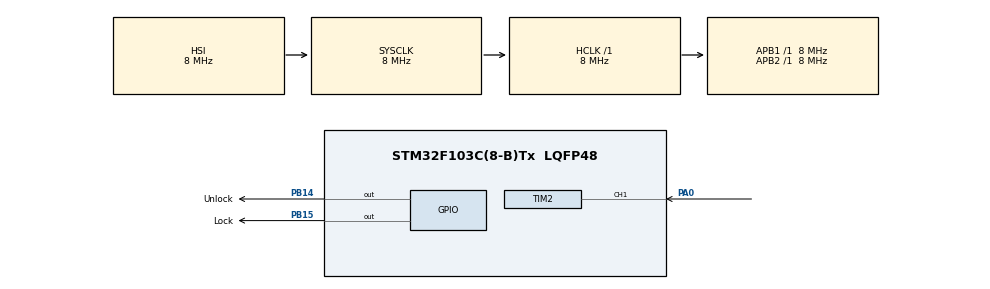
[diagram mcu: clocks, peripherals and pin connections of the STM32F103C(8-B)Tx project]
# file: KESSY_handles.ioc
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Mcu.Family=STM32F1
Mcu.Name=STM32F103C(8-B)Tx
Mcu.Package=LQFP48
NVIC.PriorityGroup=NVIC_PRIORITYGROUP_4
NVIC.TIM2_IRQn=true\:0\:0\:false\:false\:true\:true\:true\:true
NVIC.TIM3_IRQn=true\:0\:0\:false\:false\:true\:true\:true\:true
PA0-WKUP.Signal=S_TIM2_CH1_ETR
PB14.GPIO_Label=Unlock
PB14.Signal=GPIO_Output
PB15.GPIO_Label=Lock
PB15.Signal=GPIO_Output
ProjectManager.HeapSize=0x200
ProjectManager.StackSize=0x400
ProjectManager.TargetToolchain=MDK-ARM V5.32
RCC.AHBFreq_Value=8000000
RCC.APB1Freq_Value=8000000
RCC.APB1TimFreq_Value=8000000
RCC.APB2Freq_Value=8000000
RCC.APB2TimFreq_Value=8000000
RCC.HCLKFreq_Value=8000000
RCC.SYSCLKFreq_VALUE=8000000
RCC.USBFreq_Value=8000000
SH.S_TIM2_CH1_ETR.0=TIM2_CH1,Input_Capture1_from_TI1
TIM2.Channel-Input_Capture1_from_TI1=TIM_CHANNEL_1
TIM2.Channel-Input_Capture2_from_TI1_63=TIM_CHANNEL_2
TIM2.ICPolarity_CH1=TIM_INPUTCHANNELPOLARITY_FALLING
TIM2.Period=10000
TIM2.Prescaler=79
TIM3.Period=10000
TIM3.Prescaler=79
VP_SYS_VS_ND.Mode=No_Debug
VP_TIM2_VS_ClockSourceINT.Mode=Internal
VP_TIM2_VS_indirect_ch1.Mode=Input_Capture2_from_TI1_63
VP_TIM3_VS_ClockSourceINT.Mode=Internal
board=custom

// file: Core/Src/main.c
/* USER CODE BEGIN Header */
/**
  ******************************************************************************
  * @file           : main.c
  * @brief          : Main program body
  ******************************************************************************
  * @attention
  *
  * Copyright (c) 2023 STMicroelectronics.
  * All rights reserved.
  *
  * This software is licensed under terms that can be found in the LICENSE file
  * in the root directory of this software component.
  * If no LICENSE file comes with this software, it is provided AS-IS.
  *
  ******************************************************************************
  */
/* USER CODE END Header */
#include "main.h"

TIM_HandleTypeDef htim2;
TIM_HandleTypeDef htim3;

void SystemClock_Config(void);
static void MX_GPIO_Init(void);
static void MX_TIM2_Init(void);
static void MX_TIM3_Init(void);
/* USER CODE BEGIN PFP */
uint32_t period = 0;
uint32_t pulseWidth = 0;
/* USER CODE END PFP */

int main(void)
{

  /* MCU Configuration--------------------------------------------------------*/

  /* Reset of all peripherals, Initializes the Flash interface and the Systick. */
  HAL_Init();

  /* Configure the system clock */
  SystemClock_Config();

  /* Initialize all configured peripherals */
  MX_GPIO_Init();
  MX_TIM2_Init();
  MX_TIM3_Init();
  /* USER CODE BEGIN 2 */
  HAL_TIM_IC_Start_IT(&htim2, TIM_CHANNEL_1);
  HAL_TIM_IC_Start_IT(&htim2, TIM_CHANNEL_2);
	HAL_TIM_Base_Start_IT(&htim3);
  /* USER CODE END 2 */

  /* Infinite loop */
  while (1)
  {

  }
}

void SystemClock_Config(void)
{
  RCC_OscInitTypeDef RCC_OscInitStruct = {0};
  RCC_ClkInitTypeDef RCC_ClkInitStruct = {0};

  /** Initializes the RCC Oscillators according to the specified parameters
  * in the RCC_OscInitTypeDef structure.
  */
  RCC_OscInitStruct.OscillatorType = RCC_OSCILLATORTYPE_HSI;
  RCC_OscInitStruct.HSIState = RCC_HSI_ON;
  RCC_OscInitStruct.HSICalibrationValue = RCC_HSICALIBRATION_DEFAULT;
  RCC_OscInitStruct.PLL.PLLState = RCC_PLL_NONE;
  if (HAL_RCC_OscConfig(&RCC_OscInitStruct) != HAL_OK)
  {
    Error_Handler();
  }

  /** Initializes the CPU, AHB and APB buses clocks
  */
  RCC_ClkInitStruct.ClockType = RCC_CLOCKTYPE_HCLK|RCC_CLOCKTYPE_SYSCLK
                              |RCC_CLOCKTYPE_PCLK1|RCC_CLOCKTYPE_PCLK2;
  RCC_ClkInitStruct.SYSCLKSource = RCC_SYSCLKSOURCE_HSI;
  RCC_ClkInitStruct.AHBCLKDivider = RCC_SYSCLK_DIV1;
  RCC_ClkInitStruct.APB1CLKDivider = RCC_HCLK_DIV1;
  RCC_ClkInitStruct.APB2CLKDivider = RCC_HCLK_DIV1;

  if (HAL_RCC_ClockConfig(&RCC_ClkInitStruct, FLASH_LATENCY_0) != HAL_OK)
  {
    Error_Handler();
  }
}

static void MX_TIM2_Init(void)
{

  TIM_ClockConfigTypeDef sClockSourceConfig = {0};
  TIM_MasterConfigTypeDef sMasterConfig = {0};
  TIM_IC_InitTypeDef sConfigIC = {0};

  htim2.Instance = TIM2;
  htim2.Init.Prescaler = 79;
  htim2.Init.CounterMode = TIM_COUNTERMODE_UP;
  htim2.Init.Period = 10000;
  htim2.Init.ClockDivision = TIM_CLOCKDIVISION_DIV1;
  htim2.Init.AutoReloadPreload = TIM_AUTORELOAD_PRELOAD_DISABLE;
  if (HAL_TIM_Base_Init(&htim2) != HAL_OK)
  {
    Error_Handler();
  }
  sClockSourceConfig.ClockSource = TIM_CLOCKSOURCE_INTERNAL;
  if (HAL_TIM_ConfigClockSource(&htim2, &sClockSourceConfig) != HAL_OK)
  {
    Error_Handler();
  }
  if (HAL_TIM_IC_Init(&htim2) != HAL_OK)
  {
    Error_Handler();
  }
  sMasterConfig.MasterOutputTrigger = TIM_TRGO_RESET;
  sMasterConfig.MasterSlaveMode = TIM_MASTERSLAVEMODE_DISABLE;
  if (HAL_TIMEx_MasterConfigSynchronization(&htim2, &sMasterConfig) != HAL_OK)
  {
    Error_Handler();
  }
  sConfigIC.ICPolarity = TIM_INPUTCHANNELPOLARITY_FALLING;
  sConfigIC.ICSelection = TIM_ICSELECTION_DIRECTTI;
  sConfigIC.ICPrescaler = TIM_ICPSC_DIV1;
  sConfigIC.ICFilter = 0;
  if (HAL_TIM_IC_ConfigChannel(&htim2, &sConfigIC, TIM_CHANNEL_1) != HAL_OK)
  {
    Error_Handler();
  }
  sConfigIC.ICPolarity = TIM_INPUTCHANNELPOLARITY_RISING;
  sConfigIC.ICSelection = TIM_ICSELECTION_INDIRECTTI;
  if (HAL_TIM_IC_ConfigChannel(&htim2, &sConfigIC, TIM_CHANNEL_2) != HAL_OK)
  {
    Error_Handler();
  }

}

static void MX_TIM3_Init(void)
{

  TIM_ClockConfigTypeDef sClockSourceConfig = {0};
  TIM_MasterConfigTypeDef sMasterConfig = {0};

  htim3.Instance = TIM3;
  htim3.Init.Prescaler = 79;
  htim3.Init.CounterMode = TIM_COUNTERMODE_UP;
  htim3.Init.Period = 10000;
  htim3.Init.ClockDivision = TIM_CLOCKDIVISION_DIV1;
  htim3.Init.AutoReloadPreload = TIM_AUTORELOAD_PRELOAD_DISABLE;
  if (HAL_TIM_Base_Init(&htim3) != HAL_OK)
  {
    Error_Handler();
  }
  sClockSourceConfig.ClockSource = TIM_CLOCKSOURCE_INTERNAL;
  if (HAL_TIM_ConfigClockSource(&htim3, &sClockSourceConfig) != HAL_OK)
  {
    Error_Handler();
  }
  sMasterConfig.MasterOutputTrigger = TIM_TRGO_RESET;
  sMasterConfig.MasterSlaveMode = TIM_MASTERSLAVEMODE_DISABLE;
  if (HAL_TIMEx_MasterConfigSynchronization(&htim3, &sMasterConfig) != HAL_OK)
  {
    Error_Handler();
  }

}

static void MX_GPIO_Init(void)
{
  GPIO_InitTypeDef GPIO_InitStruct = {0};

  /* GPIO Ports Clock Enable */
  __HAL_RCC_GPIOA_CLK_ENABLE();
  __HAL_RCC_GPIOB_CLK_ENABLE();

  /*Configure GPIO pin Output Level */
  HAL_GPIO_WritePin(GPIOB, GPIO_PIN_14|GPIO_PIN_15, GPIO_PIN_RESET);

  /*Configure GPIO pins : PB14 PB15 */
  GPIO_InitStruct.Pin = GPIO_PIN_14|GPIO_PIN_15;
  GPIO_InitStruct.Mode = GPIO_MODE_OUTPUT_PP;
  GPIO_InitStruct.Pull = GPIO_NOPULL;
  GPIO_InitStruct.Speed = GPIO_SPEED_FREQ_LOW;
  HAL_GPIO_Init(GPIOB, &GPIO_InitStruct);

}

/* USER CODE BEGIN 4 */
void HAL_TIM_IC_CaptureCallback(TIM_HandleTypeDef *htim)
{
  if (htim->Instance == TIM2)
  {
    if(htim->Channel == HAL_TIM_ACTIVE_CHANNEL_1)
    {
      period = HAL_TIM_ReadCapturedValue(&htim2, TIM_CHANNEL_1);
      pulseWidth = HAL_TIM_ReadCapturedValue(&htim2, TIM_CHANNEL_2);

      TIM2->CNT = 0;

			if (pulseWidth >= (Lock_Pulse_Width_ms - Tolerance_ms) * 100 &&
				pulseWidth <= (Lock_Pulse_Width_ms + Tolerance_ms) * 100 &&
				(period - pulseWidth) >= (Pause_width_ms - Tolerance_ms) * 100 &&
				(period - pulseWidth) <= (Pause_width_ms + Tolerance_ms) * 100)
		{
			HAL_GPIO_WritePin(Lock_GPIO_Port, Lock_Pin, GPIO_PIN_SET);
			TIM3->CNT = 0;
		}

		if (pulseWidth >= (Unlock_Pulse_Width_ms - Tolerance_ms) * 100 &&
				pulseWidth <= (Unlock_Pulse_Width_ms + Tolerance_ms) * 100 &&
				(period - pulseWidth) >= (Pause_width_ms - Tolerance_ms) * 100 &&
				(period - pulseWidth) <= (Pause_width_ms + Tolerance_ms) * 100)
		{
			HAL_GPIO_WritePin(Unlock_GPIO_Port, Unlock_Pin, GPIO_PIN_SET);
			TIM3->CNT = 0;
		}
    }
  }
}

void HAL_TIM_PeriodElapsedCallback(TIM_HandleTypeDef *htim)
{
	if (htim->Instance == TIM3)
	{
		HAL_GPIO_WritePin(Unlock_GPIO_Port, Unlock_Pin, GPIO_PIN_RESET);
		HAL_GPIO_WritePin(Lock_GPIO_Port, Lock_Pin, GPIO_PIN_RESET);
	}
}
/* USER CODE END 4 */

void Error_Handler(void)
{
  __disable_irq();
  while (1)
  {
  }
}
